AUTOSAR XML (schema 3.1.2)
package /Components/SWC_TqTreat
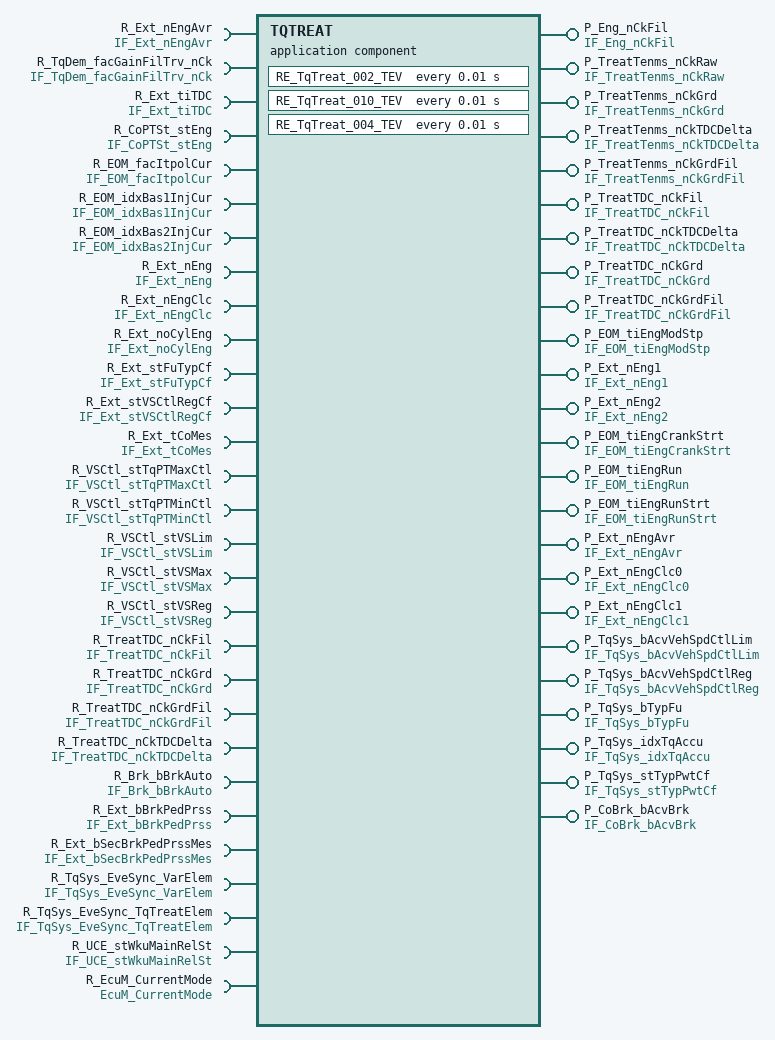
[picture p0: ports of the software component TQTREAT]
  application software component type TQTREAT
    27 x require port:
      R_Ext_nEngAvr: unqueued-receiver-com-spec{data-element=Ext_nEngAvr, init-value=Ext_nEngAvr_in, resync-time=0}, required-interface=IF_Ext_nEngAvr
      R_TqDem_facGainFilTrv_nCk: unqueued-receiver-com-spec{data-element=TqDem_facGainFilTrv_nCk, init-value=ConstantValue, resync-time=0}, required-interface=IF_TqDem_facGainFilTrv_nCk
      R_Ext_tiTDC: unqueued-receiver-com-spec{data-element=Ext_tiTDC, init-value=ConstantValue1, resync-time=0}, required-interface=IF_Ext_tiTDC
      R_CoPTSt_stEng: unqueued-receiver-com-spec{data-element=CoPTSt_stEng, init-value=ConstantValue3, resync-time=0}, required-interface=IF_CoPTSt_stEng
      R_EOM_facItpolCur: unqueued-receiver-com-spec{data-element=EOM_facItpolCur, init-value=EOM_facItpolCur_in, resync-time=0}, required-interface=IF_EOM_facItpolCur
      R_EOM_idxBas1InjCur: unqueued-receiver-com-spec{data-element=EOM_idxBas1InjCur, init-value=EOM_idxBas1InjCur_in, resync-time=0}, required-interface=IF_EOM_idxBas1InjCur
      R_EOM_idxBas2InjCur: unqueued-receiver-com-spec{data-element=EOM_idxBas2InjCur, init-value=EOM_idxBas2InjCur_in, resync-time=0}, required-interface=IF_EOM_idxBas2InjCur
      R_Ext_nEng: unqueued-receiver-com-spec{data-element=Ext_nEng, init-value=ConstantValue5, resync-time=0}, required-interface=IF_Ext_nEng
      R_Ext_nEngClc: unqueued-receiver-com-spec{data-element=Ext_nEngClc, init-value=Ext_nEngClc_in, resync-time=0}, required-interface=IF_Ext_nEngClc
      R_Ext_noCylEng: unqueued-receiver-com-spec{data-element=Ext_noCylEng, init-value=ConstantValue7, resync-time=0}, required-interface=IF_Ext_noCylEng
      R_Ext_stFuTypCf: unqueued-receiver-com-spec{data-element=Ext_stFuTypCf, init-value=ConstantValue9, resync-time=0}, required-interface=IF_Ext_stFuTypCf
      R_Ext_stVSCtlRegCf: unqueued-receiver-com-spec{data-element=Ext_stVSCtlRegCf, init-value=Ext_stVSCtlRegCf_in, resync-time=0}, required-interface=IF_Ext_stVSCtlRegCf
      R_Ext_tCoMes: unqueued-receiver-com-spec{data-element=Ext_tCoMes, init-value=ConstantValue11, resync-time=0}, required-interface=IF_Ext_tCoMes
      R_VSCtl_stTqPTMaxCtl: unqueued-receiver-com-spec{data-element=VSCtl_stTqPTMaxCtl, init-value=VSCtl_stTqPTMaxCtl_in, resync-time=0}, required-interface=IF_VSCtl_stTqPTMaxCtl
      R_VSCtl_stTqPTMinCtl: unqueued-receiver-com-spec{data-element=VSCtl_stTqPTMinCtl, init-value=VSCtl_stTqPTMinCtl_in, resync-time=0}, required-interface=IF_VSCtl_stTqPTMinCtl
      R_VSCtl_stVSLim: unqueued-receiver-com-spec{data-element=VSCtl_stVSLim, init-value=VSCtl_stVSLim_in, resync-time=0}, required-interface=IF_VSCtl_stVSLim
      R_VSCtl_stVSMax: unqueued-receiver-com-spec{data-element=VSCtl_stVSMax, init-value=VSCtl_stVSMax_in, resync-time=0}, required-interface=IF_VSCtl_stVSMax
      R_VSCtl_stVSReg: unqueued-receiver-com-spec{data-element=VSCtl_stVSReg, init-value=VSCtl_stVSReg_in, resync-time=0}, required-interface=IF_VSCtl_stVSReg
      R_TreatTDC_nCkFil: unqueued-receiver-com-spec{data-element=TreatTDC_nCkFil, init-value=ConstantValue13, resync-time=0}, required-interface=IF_TreatTDC_nCkFil
      R_TreatTDC_nCkGrd: unqueued-receiver-com-spec{data-element=TreatTDC_nCkGrd, init-value=ConstantValue15, resync-time=0}, required-interface=IF_TreatTDC_nCkGrd
      R_TreatTDC_nCkGrdFil: unqueued-receiver-com-spec{data-element=TreatTDC_nCkGrdFil, init-value=ConstantValue17, resync-time=0}, required-interface=IF_TreatTDC_nCkGrdFil
      R_TreatTDC_nCkTDCDelta: unqueued-receiver-com-spec{data-element=TreatTDC_nCkTDCDelta, init-value=ConstantValue19, resync-time=0}, required-interface=IF_TreatTDC_nCkTDCDelta
      R_Brk_bBrkAuto: unqueued-receiver-com-spec{data-element=Brk_bBrkAuto, init-value=Brk_bBrkAuto_in, resync-time=0}, required-interface=IF_Brk_bBrkAuto
      R_Ext_bBrkPedPrss: unqueued-receiver-com-spec{data-element=Ext_bBrkPedPrss, init-value=ConstantValue21, resync-time=0}, required-interface=IF_Ext_bBrkPedPrss
      R_Ext_bSecBrkPedPrssMes: unqueued-receiver-com-spec{data-element=Ext_bSecBrkPedPrssMes, init-value=ConstantValue23, resync-time=0}, required-interface=IF_Ext_bSecBrkPedPrssMes
      R_TqSys_EveSync_VarElem: unqueued-receiver-com-spec{data-element=TqSys_EveSync_VarElem, init-value=TqSys_EveSync_VarElem_in, resync-time=0}, required-interface=IF_TqSys_EveSync_VarElem
      R_TqSys_EveSync_TqTreatElem: unqueued-receiver-com-spec{data-element=TqSys_EveSync_TqTreatElem, init-value=TqSys_EveSync_TqTreatElem_in, resync-time=0}, required-interface=IF_TqSys_EveSync_TqTreatElem
    24 x provide port:
      P_Eng_nCkFil: unqueued-sender-com-spec{data-element=Eng_nCkFil, can-invalidate=false, init-value=ConstantValue25}, provided-interface=IF_Eng_nCkFil
      P_TreatTenms_nCkRaw: unqueued-sender-com-spec{data-element=TreatTenms_nCkRaw, can-invalidate=false, init-value=ConstantValue27}, provided-interface=IF_TreatTenms_nCkRaw
      P_TreatTenms_nCkGrd: unqueued-sender-com-spec{data-element=TreatTenms_nCkGrd, can-invalidate=false, init-value=ConstantValue29}, provided-interface=IF_TreatTenms_nCkGrd
      P_TreatTenms_nCkTDCDelta: unqueued-sender-com-spec{data-element=TreatTenms_nCkTDCDelta, can-invalidate=false, init-value=TreatTenms_nCkTDCDelta_out}, provided-interface=IF_TreatTenms_nCkTDCDelta
      P_TreatTenms_nCkGrdFil: unqueued-sender-com-spec{data-element=TreatTenms_nCkGrdFil, can-invalidate=false, init-value=ConstantValue31}, provided-interface=IF_TreatTenms_nCkGrdFil
      P_TreatTDC_nCkFil: unqueued-sender-com-spec{data-element=TreatTDC_nCkFil, can-invalidate=false, init-value=ConstantValue33}, provided-interface=IF_TreatTDC_nCkFil
      P_TreatTDC_nCkTDCDelta: unqueued-sender-com-spec{data-element=TreatTDC_nCkTDCDelta, can-invalidate=false, init-value=ConstantValue35}, provided-interface=IF_TreatTDC_nCkTDCDelta
      P_TreatTDC_nCkGrd: unqueued-sender-com-spec{data-element=TreatTDC_nCkGrd, can-invalidate=false, init-value=ConstantValue37}, provided-interface=IF_TreatTDC_nCkGrd
      P_TreatTDC_nCkGrdFil: unqueued-sender-com-spec{data-element=TreatTDC_nCkGrdFil, can-invalidate=false, init-value=ConstantValue39}, provided-interface=IF_TreatTDC_nCkGrdFil
      P_EOM_tiEngModStp: unqueued-sender-com-spec{data-element=EOM_tiEngModStp, can-invalidate=false, init-value=EOM_tiEngModStp_out}, provided-interface=IF_EOM_tiEngModStp
      P_Ext_nEng1: unqueued-sender-com-spec{data-element=Ext_nEng1, can-invalidate=false, init-value=ConstantValue41}, provided-interface=IF_Ext_nEng1
      P_Ext_nEng2: unqueued-sender-com-spec{data-element=Ext_nEng2, can-invalidate=false, init-value=ConstantValue43}, provided-interface=IF_Ext_nEng2
      P_EOM_tiEngCrankStrt: unqueued-sender-com-spec{data-element=EOM_tiEngCrankStrt, can-invalidate=false, init-value=EOM_tiEngCrankStrt_out}, provided-interface=IF_EOM_tiEngCrankStrt
      P_EOM_tiEngRun: unqueued-sender-com-spec{data-element=EOM_tiEngRun, can-invalidate=false, init-value=ConstantValue45}, provided-interface=IF_EOM_tiEngRun
      P_EOM_tiEngRunStrt: unqueued-sender-com-spec{data-element=EOM_tiEngRunStrt, can-invalidate=false, init-value=ConstantValue47}, provided-interface=IF_EOM_tiEngRunStrt
      P_Ext_nEngAvr: unqueued-sender-com-spec{data-element=Ext_nEngAvr, can-invalidate=false, init-value=Ext_nEngAvr_out}, provided-interface=IF_Ext_nEngAvr
      P_Ext_nEngClc0: unqueued-sender-com-spec{data-element=Ext_nEngClc0, can-invalidate=false, init-value=ConstantValue49}, provided-interface=IF_Ext_nEngClc0
      P_Ext_nEngClc1: unqueued-sender-com-spec{data-element=Ext_nEngClc1, can-invalidate=false, init-value=ConstantValue51}, provided-interface=IF_Ext_nEngClc1
      P_TqSys_bAcvVehSpdCtlLim: unqueued-sender-com-spec{data-element=TqSys_bAcvVehSpdCtlLim, can-invalidate=false, init-value=ConstantValue53}, provided-interface=IF_TqSys_bAcvVehSpdCtlLim
      P_TqSys_bAcvVehSpdCtlReg: unqueued-sender-com-spec{data-element=TqSys_bAcvVehSpdCtlReg, can-invalidate=false, init-value=ConstantValue55}, provided-interface=IF_TqSys_bAcvVehSpdCtlReg
      P_TqSys_bTypFu: unqueued-sender-com-spec{data-element=TqSys_bTypFu, can-invalidate=false, init-value=ConstantValue57}, provided-interface=IF_TqSys_bTypFu
      P_TqSys_idxTqAccu: unqueued-sender-com-spec{data-element=TqSys_idxTqAccu, can-invalidate=false, init-value=ConstantValue59}, provided-interface=IF_TqSys_idxTqAccu
      P_TqSys_stTypPwtCf: unqueued-sender-com-spec{data-element=TqSys_stTypPwtCf, can-invalidate=false, init-value=ConstantValue61}, provided-interface=IF_TqSys_stTypPwtCf
      P_CoBrk_bAcvBrk: unqueued-sender-com-spec{data-element=CoBrk_bAcvBrk, can-invalidate=false, init-value=CoBrk_bAcvBrk_out}, provided-interface=IF_CoBrk_bAcvBrk
    require port R_UCE_stWkuMainRelSt: required-interface=IF_UCE_stWkuMainRelSt
    require port R_EcuM_CurrentMode: required-interface=EcuM_CurrentMode
  51 x constant specification:
    Brk_bBrkAuto_in
      value:
        boolean literal Brk_bBrkAuto_in: type=DT_Brk_bBrkAuto, value=false
    CoBrk_bAcvBrk_out
      value:
        boolean literal CoBrk_bAcvBrk_out: type=DT_CoBrk_bAcvBrk, value=false
    ConstantValue
      value:
        integer literal ConstantValue: type=DT_TqDem_facGainFilTrv_nCk, value=1024
    ConstantValue1
      value:
        integer literal ConstantValue1: type=DT_Ext_tiTDC, value=100
    ConstantValue11
      value:
        integer literal ConstantValue11: type=DT_Ext_tCoMes, value=20
    ConstantValue13
      value:
        integer literal ConstantValue13: type=DT_TreatTDC_nCkFil, value=0
    ConstantValue15
      value:
        integer literal ConstantValue15: type=DT_TreatTDC_nCkGrd, value=0
    ConstantValue17
      value:
        integer literal ConstantValue17: type=DT_TreatTDC_nCkGrdFil, value=0
    ConstantValue19
      value:
        integer literal ConstantValue19: type=DT_TreatTDC_nCkTDCDelta, value=0
    ConstantValue21
      value:
        boolean literal ConstantValue21: type=DT_Ext_bBrkPedPrss, value=false
    ConstantValue23
      value:
        boolean literal ConstantValue23: type=DT_Ext_bSecBrkPedPrssMes, value=false
    ConstantValue25
      value:
        integer literal ConstantValue25: type=DT_Eng_nCkFil, value=0
    ConstantValue27
      value:
        integer literal ConstantValue27: type=DT_TreatTenms_nCkRaw, value=0
    ConstantValue29
      value:
        integer literal ConstantValue29: type=DT_TreatTenms_nCkGrd, value=0
    ConstantValue3
      value:
        integer literal ConstantValue3: type=DT_CoPTSt_stEng, value=1
    ConstantValue31
      value:
        integer literal ConstantValue31: type=DT_TreatTenms_nCkGrdFil, value=0
    ConstantValue33
      value:
        integer literal ConstantValue33: type=DT_TreatTDC_nCkFil, value=0
    ConstantValue35
      value:
        integer literal ConstantValue35: type=DT_TreatTDC_nCkTDCDelta, value=0
    ConstantValue37
      value:
        integer literal ConstantValue37: type=DT_TreatTDC_nCkGrd, value=0
    ConstantValue39
      value:
        integer literal ConstantValue39: type=DT_TreatTDC_nCkGrdFil, value=0
    ConstantValue41
      value:
        integer literal ConstantValue41: type=DT_Ext_nEng1, value=0
    ConstantValue43
      value:
        integer literal ConstantValue43: type=DT_Ext_nEng2, value=0
    ConstantValue45
      value:
        integer literal ConstantValue45: type=DT_EOM_tiEngRun, value=0
    ConstantValue47
      value:
        integer literal ConstantValue47: type=DT_EOM_tiEngRunStrt, value=0
    ConstantValue49
      value:
        integer literal ConstantValue49: type=DT_Ext_nEngClc0, value=0
    ConstantValue5
      value:
        integer literal ConstantValue5: type=DT_Ext_nEng, value=0
    ConstantValue51
      value:
        integer literal ConstantValue51: type=DT_Ext_nEngClc1, value=0
    ConstantValue53
      value:
        boolean literal ConstantValue53: type=DT_TqSys_bAcvVehSpdCtlLim, value=false
    ConstantValue55
      value:
        boolean literal ConstantValue55: type=DT_TqSys_bAcvVehSpdCtlReg, value=false
    ConstantValue57
      value:
        boolean literal ConstantValue57: type=DT_TqSys_bTypFu, value=false
    ConstantValue59
      value:
        integer literal ConstantValue59: type=DT_TqSys_idxTqAccu, value=1
    ConstantValue61
      value:
        integer literal ConstantValue61: type=DT_TqSys_stTypPwtCf, value=0
    ConstantValue7
      value:
        integer literal ConstantValue7: type=DT_Ext_noCylEng, value=1
    ConstantValue9
      value:
        integer literal ConstantValue9: type=DT_Ext_stFuTypCf, value=0
    EOM_facItpolCur_in
      value:
        integer literal EOM_facItpolCur_in: type=DT_EOM_facItpolCur, value=0
    EOM_idxBas1InjCur_in
      value:
        integer literal EOM_idxBas1InjCur_in: type=DT_EOM_idxBas1InjCur, value=1
    EOM_idxBas2InjCur_in
      value:
        integer literal EOM_idxBas2InjCur_in: type=DT_EOM_idxBas2InjCur, value=1
    EOM_tiEngCrankStrt_out
      value:
        integer literal EOM_tiEngCrankStrt_out: type=DT_EOM_tiEngCrankStrt, value=0
    EOM_tiEngModStp_out
      value:
        integer literal EOM_tiEngModStp_out: type=DT_EOM_tiEngModStp, value=0
    Ext_nEngAvr_in
      value:
        integer literal Ext_nEngAvr_in: type=DT_Ext_nEngAvr, value=0
    Ext_nEngAvr_out
      value:
        integer literal Ext_nEngAvr_out: type=DT_Ext_nEngAvr, value=0
    Ext_nEngClc_in
      value:
        integer literal Ext_nEngClc_in: type=DT_Ext_nEngClc, value=0
    Ext_stVSCtlRegCf_in
      value:
        integer literal Ext_stVSCtlRegCf_in: type=DT_Ext_stVSCtlRegCf, value=1
    TqSys_EveSync_TqTreatElem_in
      value:
        boolean literal TqSys_EveSync_TqTreatElem_in: type=DT_TqSys_EveSync_TqTreatElem, value=false
    TqSys_EveSync_VarElem_in
      value:
        boolean literal TqSys_EveSync_VarElem_in: type=DT_TqSys_EveSync_VarElem, value=false
    TreatTenms_nCkTDCDelta_out
      value:
        integer literal TreatTenms_nCkTDCDelta_out: type=DT_TreatTenms_nCkTDCDelta, value=0
    VSCtl_stTqPTMaxCtl_in
      value:
        integer literal VSCtl_stTqPTMaxCtl_in: type=DT_VSCtl_stTqPTMaxCtl, value=0
    VSCtl_stTqPTMinCtl_in
      value:
        integer literal VSCtl_stTqPTMinCtl_in: type=DT_VSCtl_stTqPTMinCtl, value=0
    VSCtl_stVSLim_in
      value:
        integer literal VSCtl_stVSLim_in: type=DT_VSCtl_stVSLim, value=0
    VSCtl_stVSMax_in
      value:
        integer literal VSCtl_stVSMax_in: type=DT_VSCtl_stVSMax, value=0
    VSCtl_stVSReg_in
      value:
        integer literal VSCtl_stVSReg_in: type=DT_VSCtl_stVSReg, value=0
  internal behavior IB_TqTreat: component=TQTREAT
    timing event EV_TqTreat_002_TEV: mode-dependency=dependent-on-mode=[R_UCE_stWkuMainRelSt.RCD_stWkuMainRelSt.PreMainWakeUp, R_UCE_stWkuMainRelSt.RCD_stWkuMainRelSt.PostMainWakeUp, R_UCE_stWkuMainRelSt.RCD_stWkuMainRelSt.Invalid], start-on-event=RE_TqTreat_002_TEV, period=0.01
    timing event EV_TqTreat_010_TEV: mode-dependency=dependent-on-mode=[R_UCE_stWkuMainRelSt.RCD_stWkuMainRelSt.PreMainWakeUp, R_UCE_stWkuMainRelSt.RCD_stWkuMainRelSt.PostMainWakeUp, R_UCE_stWkuMainRelSt.RCD_stWkuMainRelSt.Invalid], start-on-event=RE_TqTreat_010_TEV, period=0.01
    mode switch event EV_TqTreat_003_MSE: start-on-event=RE_TqTreat_003_MSE, activation=ENTRY, mode=R_EcuM_CurrentMode.currentMode.RUN
    timing event EV_TqTreat_004_TEV: mode-dependency=dependent-on-mode=[R_UCE_stWkuMainRelSt.RCD_stWkuMainRelSt.PreMainWakeUp, R_UCE_stWkuMainRelSt.RCD_stWkuMainRelSt.PostMainWakeUp, R_UCE_stWkuMainRelSt.RCD_stWkuMainRelSt.Invalid], start-on-event=RE_TqTreat_004_TEV, period=0.01
    data received event EV_TqTreat_006_DRE: start-on-event=RE_TqTreat_006_DRE, data=R_TqSys_EveSync_VarElem.TqSys_EveSync_VarElem
    mode switch event EV_TqTreat_005_MSE: start-on-event=RE_TqTreat_005_MSE, activation=ENTRY, mode=R_EcuM_CurrentMode.currentMode.RUN
    data received event EV_TqTreat_008_DRE: start-on-event=RE_TqTreat_008_DRE, data=R_TqSys_EveSync_TqTreatElem.TqSys_EveSync_TqTreatElem
    mode switch event EV_TqTreat_007_MSE: start-on-event=RE_TqTreat_007_MSE, activation=ENTRY, mode=R_EcuM_CurrentMode.currentMode.RUN
    mode switch event EV_TqTreat_001_MSE: start-on-event=RE_TqTreat_001_MSE, activation=ENTRY, mode=R_EcuM_CurrentMode.currentMode.RUN
    mode switch event EV_TqTreat_009_MSE: start-on-event=RE_TqTreat_009_MSE, activation=ENTRY, mode=R_EcuM_CurrentMode.currentMode.RUN
    10 x runnable:
      RE_TqTreat_008_DRE
        4 x data receive point:
          dr_Ext_tiTDC: data-element=R_Ext_tiTDC.Ext_tiTDC
          dr_TqDem_facGainFilTrv_nCk: data-element=R_TqDem_facGainFilTrv_nCk.TqDem_facGainFilTrv_nCk
          dr_Ext_nEng: data-element=R_Ext_nEng.Ext_nEng
          dr_TqSys_EveSync_TqTreatElem: data-element=R_TqSys_EveSync_TqTreatElem.TqSys_EveSync_TqTreatElem
        4 x data send point:
          ds_TreatTDC_nCkGrd: data-element=P_TreatTDC_nCkGrd.TreatTDC_nCkGrd
          ds_TreatTDC_nCkFil: data-element=P_TreatTDC_nCkFil.TreatTDC_nCkFil
          ds_TreatTDC_nCkTDCDelta: data-element=P_TreatTDC_nCkTDCDelta.TreatTDC_nCkTDCDelta
          ds_TreatTDC_nCkGrdFil: data-element=P_TreatTDC_nCkGrdFil.TreatTDC_nCkGrdFil
      RE_TqTreat_002_TEV
        6 x data receive point:
          dr_Ext_nEng: data-element=R_Ext_nEng.Ext_nEng
          dr_TreatTDC_nCkFil: data-element=R_TreatTDC_nCkFil.TreatTDC_nCkFil
          dr_TreatTDC_nCkGrd: data-element=R_TreatTDC_nCkGrd.TreatTDC_nCkGrd
          dr_TreatTDC_nCkGrdFil: data-element=R_TreatTDC_nCkGrdFil.TreatTDC_nCkGrdFil
          dr_Ext_nEngAvr: data-element=R_Ext_nEngAvr.Ext_nEngAvr
          dr_TreatTDC_nCkTDCDelta: data-element=R_TreatTDC_nCkTDCDelta.TreatTDC_nCkTDCDelta
        5 x data send point:
          ds_TreatTenms_nCkRaw: data-element=P_TreatTenms_nCkRaw.TreatTenms_nCkRaw
          ds_Eng_nCkFil: data-element=P_Eng_nCkFil.Eng_nCkFil
          ds_TreatTenms_nCkGrd: data-element=P_TreatTenms_nCkGrd.TreatTenms_nCkGrd
          ds_TreatTenms_nCkTDCDelta: data-element=P_TreatTenms_nCkTDCDelta.TreatTenms_nCkTDCDelta
          ds_TreatTenms_nCkGrdFil: data-element=P_TreatTenms_nCkGrdFil.TreatTenms_nCkGrdFil
      RE_TqTreat_005_MSE
        5 x data send point:
          ds_Ext_nEngClc0: data-element=P_Ext_nEngClc0.Ext_nEngClc0
          ds_Ext_nEngAvr: data-element=P_Ext_nEngAvr.Ext_nEngAvr
          ds_Ext_nEng2: data-element=P_Ext_nEng2.Ext_nEng2
          ds_Ext_nEngClc1: data-element=P_Ext_nEngClc1.Ext_nEngClc1
          ds_Ext_nEng1: data-element=P_Ext_nEng1.Ext_nEng1
      RE_TqTreat_007_MSE
        4 x data send point:
          ds_TreatTDC_nCkGrdFil: data-element=P_TreatTDC_nCkGrdFil.TreatTDC_nCkGrdFil
          ds_TreatTDC_nCkFil: data-element=P_TreatTDC_nCkFil.TreatTDC_nCkFil
          ds_TreatTDC_nCkTDCDelta: data-element=P_TreatTDC_nCkTDCDelta.TreatTDC_nCkTDCDelta
          ds_TreatTDC_nCkGrd: data-element=P_TreatTDC_nCkGrd.TreatTDC_nCkGrd
      RE_TqTreat_004_TEV
        13 x data receive point:
          dr_VSCtl_stTqPTMinCtl: data-element=R_VSCtl_stTqPTMinCtl.VSCtl_stTqPTMinCtl
          dr_VSCtl_stVSMax: data-element=R_VSCtl_stVSMax.VSCtl_stVSMax
          dr_CoPTSt_stEng: data-element=R_CoPTSt_stEng.CoPTSt_stEng
          dr_EOM_facItpolCur: data-element=R_EOM_facItpolCur.EOM_facItpolCur
          dr_Ext_stFuTypCf: data-element=R_Ext_stFuTypCf.Ext_stFuTypCf
          dr_Ext_tCoMes: data-element=R_Ext_tCoMes.Ext_tCoMes
          dr_EOM_idxBas2InjCur: data-element=R_EOM_idxBas2InjCur.EOM_idxBas2InjCur
          dr_Ext_nEng: data-element=R_Ext_nEng.Ext_nEng
          dr_VSCtl_stVSLim: data-element=R_VSCtl_stVSLim.VSCtl_stVSLim
          dr_VSCtl_stTqPTMaxCtl: data-element=R_VSCtl_stTqPTMaxCtl.VSCtl_stTqPTMaxCtl
          dr_Ext_stVSCtlRegCf: data-element=R_Ext_stVSCtlRegCf.Ext_stVSCtlRegCf
          dr_EOM_idxBas1InjCur: data-element=R_EOM_idxBas1InjCur.EOM_idxBas1InjCur
          dr_VSCtl_stVSReg: data-element=R_VSCtl_stVSReg.VSCtl_stVSReg
        9 x data send point:
          ds_EOM_tiEngRun: data-element=P_EOM_tiEngRun.EOM_tiEngRun
          ds_EOM_tiEngRunStrt: data-element=P_EOM_tiEngRunStrt.EOM_tiEngRunStrt
          ds_TqSys_stTypPwtCf: data-element=P_TqSys_stTypPwtCf.TqSys_stTypPwtCf
          ds_EOM_tiEngModStp: data-element=P_EOM_tiEngModStp.EOM_tiEngModStp
          ds_TqSys_idxTqAccu: data-element=P_TqSys_idxTqAccu.TqSys_idxTqAccu
          ds_EOM_tiEngCrankStrt: data-element=P_EOM_tiEngCrankStrt.EOM_tiEngCrankStrt
          ds_TqSys_bTypFu: data-element=P_TqSys_bTypFu.TqSys_bTypFu
          ds_TqSys_bAcvVehSpdCtlLim: data-element=P_TqSys_bAcvVehSpdCtlLim.TqSys_bAcvVehSpdCtlLim
          ds_TqSys_bAcvVehSpdCtlReg: data-element=P_TqSys_bAcvVehSpdCtlReg.TqSys_bAcvVehSpdCtlReg
      RE_TqTreat_010_TEV
        data receive point dr_Ext_bSecBrkPedPrssMes: data-element=R_Ext_bSecBrkPedPrssMes.Ext_bSecBrkPedPrssMes
        data receive point dr_Brk_bBrkAuto: data-element=R_Brk_bBrkAuto.Brk_bBrkAuto
        data receive point dr_Ext_bBrkPedPrss: data-element=R_Ext_bBrkPedPrss.Ext_bBrkPedPrss
        data send point ds_CoBrk_bAcvBrk: data-element=P_CoBrk_bAcvBrk.CoBrk_bAcvBrk
      RE_TqTreat_003_MSE
        9 x data send point:
          ds_TqSys_bTypFu: data-element=P_TqSys_bTypFu.TqSys_bTypFu
          ds_TqSys_bAcvVehSpdCtlReg: data-element=P_TqSys_bAcvVehSpdCtlReg.TqSys_bAcvVehSpdCtlReg
          ds_EOM_tiEngCrankStrt: data-element=P_EOM_tiEngCrankStrt.EOM_tiEngCrankStrt
          ds_EOM_tiEngRun: data-element=P_EOM_tiEngRun.EOM_tiEngRun
          ds_EOM_tiEngRunStrt: data-element=P_EOM_tiEngRunStrt.EOM_tiEngRunStrt
          ds_EOM_tiEngModStp: data-element=P_EOM_tiEngModStp.EOM_tiEngModStp
          ds_TqSys_stTypPwtCf: data-element=P_TqSys_stTypPwtCf.TqSys_stTypPwtCf
          ds_TqSys_idxTqAccu: data-element=P_TqSys_idxTqAccu.TqSys_idxTqAccu
          ds_TqSys_bAcvVehSpdCtlLim: data-element=P_TqSys_bAcvVehSpdCtlLim.TqSys_bAcvVehSpdCtlLim
      RE_TqTreat_009_MSE
        data send point ds_CoBrk_bAcvBrk: data-element=P_CoBrk_bAcvBrk.CoBrk_bAcvBrk
      RE_TqTreat_001_MSE
        5 x data send point:
          ds_TreatTenms_nCkRaw: data-element=P_TreatTenms_nCkRaw.TreatTenms_nCkRaw
          ds_TreatTenms_nCkGrdFil: data-element=P_TreatTenms_nCkGrdFil.TreatTenms_nCkGrdFil
          ds_TreatTenms_nCkGrd: data-element=P_TreatTenms_nCkGrd.TreatTenms_nCkGrd
          ds_Eng_nCkFil: data-element=P_Eng_nCkFil.Eng_nCkFil
          ds_TreatTenms_nCkTDCDelta: data-element=P_TreatTenms_nCkTDCDelta.TreatTenms_nCkTDCDelta
      RE_TqTreat_006_DRE
        4 x data receive point:
          dr_Ext_nEngClc: data-element=R_Ext_nEngClc.Ext_nEngClc
          dr_TqSys_EveSync_VarElem: data-element=R_TqSys_EveSync_VarElem.TqSys_EveSync_VarElem
          dr_Ext_noCylEng: data-element=R_Ext_noCylEng.Ext_noCylEng
          dr_Ext_nEng: data-element=R_Ext_nEng.Ext_nEng
        5 x data send point:
          ds_Ext_nEngClc0: data-element=P_Ext_nEngClc0.Ext_nEngClc0
          ds_Ext_nEng1: data-element=P_Ext_nEng1.Ext_nEng1
          ds_Ext_nEng2: data-element=P_Ext_nEng2.Ext_nEng2
          ds_Ext_nEngClc1: data-element=P_Ext_nEngClc1.Ext_nEngClc1
          ds_Ext_nEngAvr: data-element=P_Ext_nEngAvr.Ext_nEngAvr
  swc implementation Imp_TqTreat: programming-language=C, behavior=IB_TqTreat
    code-descriptors:
      code CodeDescriptor: type=SRC
        23 x xfile:
          TqTreat_004_calibrations_c: url=TqTreat_004_calibrations.c
          TqTreat_002_TEV_fct_h: url=TqTreat_002_TEV_fct.h
          TqTreat_MemMap_h: url=TqTreat_MemMap.h
          TqTreat_004_TEV_fct_h: url=TqTreat_004_TEV_fct.h
          TqTreat_006_DRE_fct_c: url=TqTreat_006_DRE_fct.c
          TqTreat_c: url=TqTreat.c
          TqTreat_h: url=TqTreat.h
          TqTreat_002_calibrations_h: url=TqTreat_002_calibrations.h
          TqTreat_010_TEV_fct_h: url=TqTreat_010_TEV_fct.h
          TqTreat_006_calibrations_h: url=TqTreat_006_calibrations.h
          TqTreat_008_calibrations_c: url=TqTreat_008_calibrations.c
          TqTreat_008_DRE_fct_h: url=TqTreat_008_DRE_fct.h
          TqTreat_006_calibrations_c: url=TqTreat_006_calibrations.c
          TqTreat_004_lut_c: url=TqTreat_004_lut.c
          TqTreat_002_calibrations_c: url=TqTreat_002_calibrations.c
          TqTreat_010_TEV_fct_c: url=TqTreat_010_TEV_fct.c
          TqTreat_008_calibrations_h: url=TqTreat_008_calibrations.h
          TqTreat_008_DRE_fct_c: url=TqTreat_008_DRE_fct.c
          TqTreat_004_calibrations_h: url=TqTreat_004_calibrations.h
          TqTreat_002_TEV_fct_c: url=TqTreat_002_TEV_fct.c
          TqTreat_004_TEV_fct_c: url=TqTreat_004_TEV_fct.c
          TqTreat_006_DRE_fct_h: url=TqTreat_006_DRE_fct.h
          TqTreat_004_lut_h: url=TqTreat_004_lut.h
